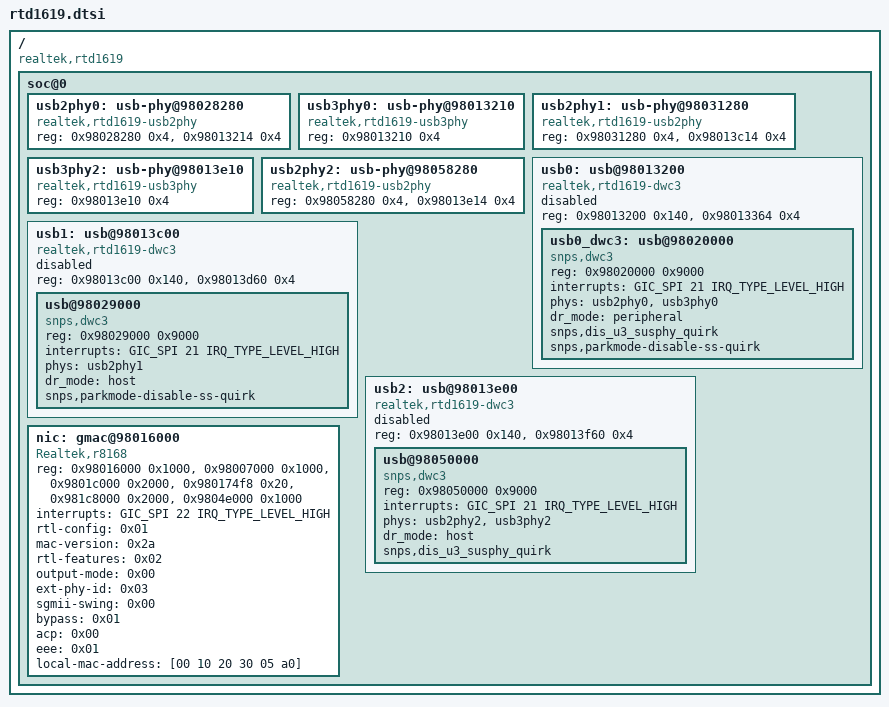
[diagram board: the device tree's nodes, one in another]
// SPDX-License-Identifier: (GPL-2.0-or-later OR BSD-2-Clause)
/*
 * Realtek RTD1619 SoC
 *
 * Copyright (c) 2019 Realtek Semiconductor Corp.
 */

#include "rtd16xx.dtsi"

/ {
	compatible = "realtek,rtd1619";

	soc@0 {
		usb2phy0: usb-phy@98028280 {
			compatible = "realtek,rtd1619-usb2phy";
			reg = <0x98028280 0x4>, <0x98013214 0x4>;
			#phy-cells = <0>;
		};

		usb3phy0: usb-phy@98013210 {
			compatible = "realtek,rtd1619-usb3phy";
			reg = <0x98013210 0x4>;
			#phy-cells = <0>;
		};

		usb2phy1: usb-phy@98031280 {
			compatible = "realtek,rtd1619-usb2phy";
			reg = <0x98031280 0x4>, <0x98013c14 0x4>;
			#phy-cells = <0>;
		};

		usb3phy2: usb-phy@98013e10 {
			compatible = "realtek,rtd1619-usb3phy";
			reg = <0x98013e10 0x4>;
			#phy-cells = <0>;
		};

		usb2phy2: usb-phy@98058280 {
			compatible = "realtek,rtd1619-usb2phy";
			reg = <0x98058280 0x4>, <0x98013e14 0x4>;
			#phy-cells = <0>;
		};

		usb0: usb@98013200 {
			compatible = "realtek,rtd1619-dwc3", "realtek,rtd-dwc3";
			reg = <0x98013200 0x140>, <0x98013364 0x4>;
			#address-cells = <1>;
			#size-cells = <1>;
			ranges;
			status = "disabled";

			usb0_dwc3: usb@98020000 {
				compatible = "snps,dwc3";
				reg = <0x98020000 0x9000>;
				interrupts = <GIC_SPI 21 IRQ_TYPE_LEVEL_HIGH>;
				phys = <&usb2phy0>, <&usb3phy0>;
				phy-names = "usb2-phy", "usb3-phy";
				dr_mode = "peripheral";
				snps,dis_u3_susphy_quirk;
				snps,parkmode-disable-ss-quirk;
			};
		};

		usb1: usb@98013c00 {
			compatible = "realtek,rtd1619-dwc3", "realtek,rtd-dwc3";
			reg = <0x98013c00 0x140>, <0x98013d60 0x4>;
			#address-cells = <1>;
			#size-cells = <1>;
			ranges;
			status = "disabled";

			usb@98029000 {
				compatible = "snps,dwc3";
				reg = <0x98029000 0x9000>;
				interrupts = <GIC_SPI 21 IRQ_TYPE_LEVEL_HIGH>;
				phys = <&usb2phy1>;
				phy-names = "usb2-phy";
				dr_mode = "host";
				snps,parkmode-disable-ss-quirk;
			};
		};

		usb2: usb@98013e00 {
			compatible = "realtek,rtd1619-dwc3", "realtek,rtd-dwc3";
			reg = <0x98013e00 0x140>, <0x98013f60 0x4>;
			#address-cells = <1>;
			#size-cells = <1>;
			ranges;
			status = "disabled";

			usb@98050000 {
				compatible = "snps,dwc3";
				reg = <0x98050000 0x9000>;
				interrupts = <GIC_SPI 21 IRQ_TYPE_LEVEL_HIGH>;
				phys = <&usb2phy2>, <&usb3phy2>;
				phy-names = "usb2-phy", "usb3-phy";
				dr_mode = "host";
				snps,dis_u3_susphy_quirk;
			};
		};
		
		nic: gmac@98016000 {
			compatible = "Realtek,r8168";
			reg = <0x98016000 0x1000>,
				<0x98007000 0x1000>,
				<0x9801c000 0x2000>,
				<0x980174f8 0x20>,
				<0x981c8000 0x2000>,
				<0x9804e000 0x1000>;
			interrupts = <GIC_SPI 22 IRQ_TYPE_LEVEL_HIGH>;

			rtl-config = <0x01>;
			mac-version = <0x2a>;
			rtl-features = <0x02>;
			output-mode = <0x00>;
			ext-phy-id = <0x03>;
			sgmii-swing = <0x00>;
			bypass = <0x01>;
			acp = <0x00>;
			eee = <0x01>;
			local-mac-address = [00 10 20 30 05 a0];
			status = "okay";
		};
	};
};
